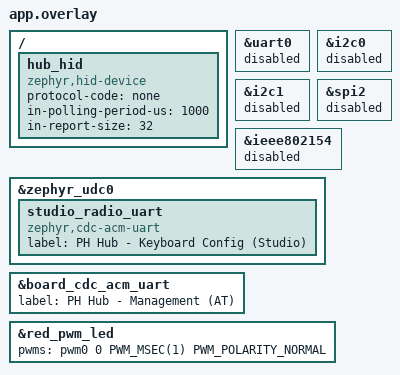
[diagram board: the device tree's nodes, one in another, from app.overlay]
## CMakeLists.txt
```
cmake_minimum_required(VERSION 3.20.0)
find_package(Zephyr REQUIRED HINTS $ENV{ZEPHYR_BASE})
project(eio_wireless_hub)
target_include_directories(app PRIVATE include src tinycrypt/include)
target_compile_options(app PRIVATE -include ${CMAKE_CURRENT_SOURCE_DIR}/include/hub-compat.h)
target_sources(app PRIVATE src/main.c src/usb.c src/usb-port-names.c src/radio.c src/ble-mouse.c src/diagnostics.c
    src/mouse-map.c src/peer-crypto.c src/peer-store.c src/input-merge.c
    src/studio-radio.c src/ph_lite_dongle_at.c src/dongle-led.c
    tinycrypt/source/aes_encrypt.c tinycrypt/source/ccm_mode.c tinycrypt/source/utils.c)
```

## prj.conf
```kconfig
CONFIG_BT=y
CONFIG_BT_CENTRAL=y
CONFIG_BT_SMP=y
# Many BLE HID mice implement legacy Just Works pairing, not LE SC.
CONFIG_BT_SMP_SC_PAIR_ONLY=n
CONFIG_BT_MAX_CONN=1
CONFIG_BT_MAX_PAIRED=1
CONFIG_BT_GATT_CLIENT=y
CONFIG_BT_GATT_DM=y
CONFIG_BT_HOGP=y
CONFIG_BT_SETTINGS=y
CONFIG_BT_PRIVACY=y
CONFIG_BT_ATT_TX_COUNT=5
CONFIG_BT_DEVICE_NAME="EIO Wireless Hub"
CONFIG_ESB=y
CONFIG_ESB_CLOCK_INIT=y
CONFIG_ESB_MPSL_TIMESLOT=y
CONFIG_MPSL_TIMESLOT_SESSION_COUNT=2
CONFIG_FLASH=y
CONFIG_FLASH_MAP=y
CONFIG_FLASH_PAGE_LAYOUT=y
CONFIG_NVS=y
CONFIG_SETTINGS=y
CONFIG_SETTINGS_NVS=y
CONFIG_USB_DEVICE_STACK_NEXT=y
CONFIG_USBD_HID_SUPPORT=y
CONFIG_CDC_ACM_SERIAL_INITIALIZE_AT_BOOT=n
CONFIG_SERIAL=y
CONFIG_UART_INTERRUPT_DRIVEN=y
CONFIG_UART_LINE_CTRL=y
CONFIG_CONSOLE=n
CONFIG_UART_CONSOLE=n
CONFIG_LOG=y
CONFIG_LOG_BACKEND_UART=n
CONFIG_USE_SEGGER_RTT=y
CONFIG_LOG_BACKEND_RTT=y
CONFIG_HWINFO=y
CONFIG_PWM=y
CONFIG_BUILD_OUTPUT_UF2=y
CONFIG_HEAP_MEM_POOL_SIZE=16384
CONFIG_BT_GATT_DM_MAX_ATTRS=96
CONFIG_BT_HOGP_REPORTS_MAX=24
CONFIG_MAIN_STACK_SIZE=4096
CONFIG_SYSTEM_WORKQUEUE_STACK_SIZE=4096
# CDC callbacks must not share a queue with BLE lifecycle/flash work.
CONFIG_USBD_CDC_ACM_WORKQUEUE=y
CONFIG_USBD_CDC_ACM_STACK_SIZE=4096
CONFIG_USBD_THREAD_STACK_SIZE=4096
CONFIG_UDC_NRF_THREAD_STACK_SIZE=1024
CONFIG_BT_TX_PROCESSOR_STACK_SIZE=1536
CONFIG_ASSERT=y
CONFIG_THREAD_STACK_INFO=y
CONFIG_REBOOT=y
CONFIG_ESB_MAX_PAYLOAD_LENGTH=32
CONFIG_ESB_PIPE_COUNT=2
CONFIG_ESB_TX_FIFO_SIZE=4
```

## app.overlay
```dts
&uart0 { status = "disabled"; };
&i2c0 { status = "disabled"; };
&i2c1 { status = "disabled"; };
&spi2 { status = "disabled"; };
&ieee802154 { status = "disabled"; };
&zephyr_udc0 {
    studio_radio_uart: studio_radio_uart {
        compatible = "zephyr,cdc-acm-uart";
        label = "PH Hub - Keyboard Config (Studio)";
    };
};
cdc_acm_uart0: &board_cdc_acm_uart { label = "PH Hub - Management (AT)"; };
dongle_status_led: &red_pwm_led { pwms = <&pwm0 0 PWM_MSEC(1) PWM_POLARITY_NORMAL>; };
/ {
    hub_hid: hub_hid {
        compatible = "zephyr,hid-device";
        protocol-code = "none";
        in-polling-period-us = <1000>;
        in-report-size = <32>;
    };
};
```

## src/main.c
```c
#include <zephyr/kernel.h>
#include <zephyr/bluetooth/bluetooth.h>
#include <zephyr/settings/settings.h>
#include <esb.h>
#include <zmk/2g4.h>
#include "hub.h"
#include "ble-mouse.h"
#include "hub-peer.h"
#include "diagnostics.h"
int main(void) {
    int err = bt_enable(NULL);
    if (err) return err;
    err = settings_load();
    if (err) return err;
    hub_peer_load_finish();
    err=hub_usb_init();if(err)return err;
    err=ble_mouse_init();if(err)return err;
    /* Keep USB diagnostics available after a fault without repeatedly writing
     * crypto epochs to flash in a reboot loop. AT+RST explicitly retries. */
    if(!hub_diagnostics_safe_mode())hub_radio_error=zmk_2g4_dongle_start();
    hub_radio_run();
    return 0;
}
```

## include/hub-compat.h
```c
#pragma once
#define CONFIG_ZMK_2G4_DONGLE 1
#define CONFIG_ZMK_2G4_AES_KEY "6D6164656279706864656973676EC0DE"
#define CONFIG_ZMK_2G4_ADDR_BASE_0 0x50
#define CONFIG_ZMK_2G4_ADDR_BASE_1 0x48
#define CONFIG_ZMK_2G4_ADDR_BASE_2 0x44
#define CONFIG_ZMK_2G4_ADDR_BASE_3 0x53
#define CONFIG_ZMK_2G4_ADDR_PREFIX 0x4e
#define CONFIG_ZMK_2G4_RF_CHANNEL 76
#define CONFIG_PH_LITE_DONGLE_AT_BOOTLOADER 1
```

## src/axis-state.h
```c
/* SPDX-License-Identifier: MIT */
#pragma once
#include <stdint.h>
static inline int16_t hub_axis_fresh(uint32_t now,uint32_t time,int16_t value){return now-time<=250?value:0;}
```

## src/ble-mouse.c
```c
/* SPDX-License-Identifier: MIT */
#include <zephyr/kernel.h>
#include <zephyr/bluetooth/bluetooth.h>
#include <zephyr/bluetooth/conn.h>
#include <zephyr/bluetooth/gatt.h>
#include <zephyr/bluetooth/hci.h>
#include <bluetooth/gatt_dm.h>
#include <bluetooth/services/hogp.h>
#include <zephyr/settings/settings.h>
#include <zephyr/sys/atomic.h>
#include <string.h>
#include "ble-mouse.h"
#include "hub.h"
#include "diagnostics.h"
static struct bt_hogp hogp;
static struct bt_conn *connection;
static struct mouse_map map;
static uint8_t report_map[2048];
static size_t map_size;
static atomic_t mouse_ready,packets,parse_errors,last_error;
static atomic_t disconnect_reason,security_level,connect_error;
static bool scanning,have_bond,discovering,protocol_configured;
static atomic_t resume_error_code,subscriptions_removed;
static int64_t pair_until;
static struct k_mutex map_lock;
struct candidate { bt_addr_le_t addr; int8_t rssi; char name[24]; };
static struct candidate candidates[8];
static unsigned candidate_count;
static struct k_mutex candidate_lock;
static struct k_work_delayable scan_work;
static struct k_work map_work;
static struct k_work subscribe_work;
static struct k_work_delayable resume_work;
static struct k_work connect_work;
static bt_addr_le_t reconnect_addr;
static bool radio_paused;
static int resume_error;
static void resume_handler(struct k_work *work) {
    if(!radio_paused)return;
    int err=hub_radio_pause(false);
    resume_error=err;
    if(err){k_work_reschedule(&resume_work,K_MSEC(50));return;}
    radio_paused=false;
}
static void scan_handler(struct k_work *work);
static void subscribe_handler(struct k_work *work);
static void map_handler(struct k_work *work);
static bool name_ad(struct bt_data *d,void *ctx) {
    struct { bool hid; char name[24]; } *a=ctx;
    if(d->type==BT_DATA_UUID16_ALL || d->type==BT_DATA_UUID16_SOME) {
        for(size_t i=0;i+1<d->data_len;i+=2)if(d->data[i]==0x12 && d->data[i+1]==0x18)a->hid=true;
    } else if(d->type==BT_DATA_GAP_APPEARANCE && d->data_len==2) {
        if(d->data[0]==0xc2 && d->data[1]==3)a->hid=true;
    } else if(d->type==BT_DATA_NAME_COMPLETE || d->type==BT_DATA_NAME_SHORTENED) {
        size_t n=MIN(d->data_len,sizeof(a->name)-1);
        for(size_t i=0;i<n;i++)a->name[i]=d->data[i]>=32 && d->data[i]<127?d->data[i]:'?';
    }
    return true;
}
static int connect_addr(const bt_addr_le_t *addr) {
    hub_diagnostic_stage(30);
    if(connection)return -EISCONN;
    bt_le_scan_stop();scanning=false;
    // Temporarily release ESB slots while the first BLE connection events settle.
    // Resume even if connection setup fails, so the keyboard cannot stay paused.
    if(!hub_radio_pause(true)){radio_paused=true;k_msleep(30);}
    k_work_reschedule(&resume_work,K_SECONDS(5));
    struct bt_conn_le_create_param create=BT_CONN_LE_CREATE_PARAM_INIT(BT_CONN_LE_OPT_NONE,160,16);
    struct bt_le_conn_param params={.interval_min=12,.interval_max=24,.latency=0,.timeout=400};
    int err=bt_conn_le_create(addr,&create,&params,&connection);
    atomic_set(&last_error,err);
    if(err)k_work_reschedule(&scan_work,K_SECONDS(1));
    return err;
}
static void connect_handler(struct k_work *work){connect_addr(&reconnect_addr);}
static void scan_recv(const struct bt_le_scan_recv_info *info,struct net_buf_simple *ad) {
    if(connection || !(info->adv_props&BT_GAP_ADV_PROP_CONNECTABLE))return;
    if(have_bond && bt_le_bond_exists(BT_ID_DEFAULT,info->addr)) {
        reconnect_addr=*info->addr;k_work_submit(&connect_work);return;
    }
    if(k_uptime_get()>=pair_until)return;
    struct { bool hid; char name[24]; } fields={0};
    struct net_buf_simple_state saved;net_buf_simple_save(ad,&saved);
    bt_data_parse(ad,name_ad,&fields);net_buf_simple_restore(ad,&saved);
    if(!fields.hid)return;
    k_mutex_lock(&candidate_lock,K_FOREVER);
    unsigned index;
    for(index=0;index<candidate_count;index++)if(!bt_addr_le_cmp(info->addr,&candidates[index].addr))break;
    if(index<ARRAY_SIZE(candidates)) {
        if(index==candidate_count)candidate_count++;
        candidates[index].addr=*info->addr;candidates[index].rssi=info->rssi;
        if(fields.name[0])memcpy(candidates[index].name,fields.name,sizeof(fields.name));
    }
    k_mutex_unlock(&candidate_lock);
}
static struct bt_le_scan_cb scan_callbacks={.recv=scan_recv};
static void scan_handler(struct k_work *work) {
    if(connection)return;
    bool pairing=k_uptime_get()<pair_until;
    if(!pairing && !have_bond) {
        if(scanning)bt_le_scan_stop();
        scanning=false;return;
    }
    if(!scanning) {
        // 10% scan duty leaves most radio time available to the keyboard.
        struct bt_le_scan_param params={.type=pairing?BT_LE_SCAN_TYPE_ACTIVE:BT_LE_SCAN_TYPE_PASSIVE,
            .options=BT_LE_SCAN_OPT_NONE,.interval=160,.window=16};
        int err=bt_le_scan_start(&params,NULL);
        scanning=!err;if(err)atomic_set(&last_error,err);
    }
    k_work_reschedule(&scan_work,K_SECONDS(1));
}
static uint8_t report_received(struct bt_hogp *h,struct bt_hogp_rep_info *rep,uint8_t err,const uint8_t *data) {
    if(err || !data) {
        atomic_clear(&mouse_ready);
        atomic_set(&last_error,err?err:-ENODATA);
        atomic_inc(&subscriptions_removed);hub_mouse_release(2);
        return BT_GATT_ITER_STOP;
    }
    if(!atomic_get(&mouse_ready))return BT_GATT_ITER_CONTINUE;
    struct mouse_event e;int rc;
    k_mutex_lock(&map_lock,K_FOREVER);
    rc=mouse_map_decode(&map,bt_hogp_rep_id(rep),data,bt_hogp_rep_size(rep),&e);
    k_mutex_unlock(&map_lock);
    if(!rc){hub_mouse_event(2,&e);atomic_inc(&packets);}
    else atomic_inc(&parse_errors);
    return BT_GATT_ITER_CONTINUE;
}
static void subscribe_handler(struct k_work *work) {
    if(!connection)return;
    k_mutex_lock(&map_lock,K_FOREVER);
    int err=mouse_map_parse(&map,report_map,map_size);
    k_mutex_unlock(&map_lock);
    if(err){atomic_set(&last_error,err);return;}
    // Report protocol preserves wheel, extra buttons and non-8-bit axes.
    if(!protocol_configured || bt_hogp_pm_get(&hogp)!=BT_HIDS_PM_REPORT) {
        /* Send Report mode explicitly even if the characteristic already reads
         * Report. Some peripherals do not activate input after first pairing
         * until the host writes its desired mode. Set before synchronous cb. */
        protocol_configured=true;
        err=bt_hogp_pm_write(&hogp,BT_HIDS_PM_REPORT);
        if(!err)return; // pm_update schedules the subscription work.
        if(err!=-EOPNOTSUPP){atomic_set(&last_error,err);return;}
    }
    bool subscribed=false;
    struct bt_hogp_rep_info *r=NULL;
    while((r=bt_hogp_rep_next(&hogp,r))) {
        bool mouse=false;
        for(int i=0;i<map.field_count;i++)if(map.fields[i].id==bt_hogp_rep_id(r))mouse=true;
        if(mouse && bt_hogp_rep_type(r)==BT_HIDS_REPORT_TYPE_INPUT) {
            err=bt_hogp_rep_subscribe(&hogp,r,report_received);
            if(err && err!=-EALREADY){atomic_set(&last_error,err);return;}
            subscribed=true;
        }
    }
    atomic_set(&mouse_ready,subscribed);atomic_set(&last_error,subscribed?0:-ENOTSUP);
    if(subscribed)atomic_set(&resume_error_code,bt_hogp_exit_suspend(&hogp));
    k_work_reschedule(&resume_work,K_MSEC(100));
}
static void map_chunk(struct bt_hogp *h,uint8_t err,const uint8_t *data,size_t size,size_t offset) {
    if(!connection)return;
    if(err==BT_ATT_ERR_INVALID_OFFSET && offset==map_size && offset>0) {
        k_work_submit(&subscribe_work);return;
    }
    if(err){atomic_set(&last_error,err);return;}
    if(offset!=map_size || offset+size>sizeof(report_map)){atomic_set(&last_error,-E2BIG);return;}
    if(!data || !size){k_work_submit(&subscribe_work);return;}
    memcpy(report_map+offset,data,size);map_size+=size;
    k_work_submit(&map_work);
}
static void map_handler(struct k_work *work) {
    if(!connection)return;
    int err=bt_hogp_map_read(&hogp,map_chunk,map_size,K_NO_WAIT);
    atomic_set(&last_error,err);
}
static void ready_cb(struct bt_hogp *h){map_size=0;k_work_submit(&map_work);}
static void prep_error(struct bt_hogp *h,int err){atomic_set(&last_error,err);}
static void pm_update(struct bt_hogp *h){if(map_size)k_work_submit(&subscribe_work);}
static void discovery_done(struct bt_gatt_dm *dm,void *context) {
    int err=bt_hogp_handles_assign(dm,&hogp);bt_gatt_dm_data_release(dm);
    atomic_set(&last_error,err);
}
static void discovery_missing(struct bt_conn *conn,void *ctx){atomic_set(&last_error,-ENOTSUP);}
static void discovery_error(struct bt_conn *conn,int err,void *ctx){atomic_set(&last_error,err);}
static const struct bt_gatt_dm_cb discovery_cb={.completed=discovery_done,
    .service_not_found=discovery_missing,.error_found=discovery_error};
static void discover(struct bt_conn *conn) {
    if(discovering)return;
    discovering=true;
    int err=bt_gatt_dm_start(conn,BT_UUID_HIDS,&discovery_cb,NULL);
    atomic_set(&last_error,err);
}
static void connected_cb(struct bt_conn *conn,uint8_t err) {
    protocol_configured=false;
    hub_diagnostic_stage(40);
    atomic_set(&connect_error,err);
    if(err) {
        atomic_set(&last_error,err);
        if(connection){bt_conn_unref(connection);connection=NULL;}
        k_work_reschedule(&scan_work,K_SECONDS(1));return;
    }
    int rc=bt_conn_set_security(conn,BT_SECURITY_L2);
    if(rc)atomic_set(&last_error,rc);
    else if(bt_conn_get_security(conn)>=BT_SECURITY_L2)discover(conn);
}
static void security_changed(struct bt_conn *conn,bt_security_t level,enum bt_security_err err) {
    hub_diagnostic_stage(41);
    atomic_set(&security_level,level);
    if(err){atomic_set(&last_error,err);return;}
    if(level>=BT_SECURITY_L2){have_bond=true;discover(conn);}
}
static void disconnected_cb(struct bt_conn *conn,uint8_t reason) {
    protocol_configured=false;
    atomic_set(&disconnect_reason,reason);atomic_clear(&security_level);
    atomic_clear(&mouse_ready);hub_mouse_release(2);
    k_work_cancel(&map_work);k_work_cancel(&subscribe_work);
    bt_hogp_release(&hogp);discovering=false;map_size=0;
    if(connection){bt_conn_unref(connection);connection=NULL;}
    k_work_reschedule(&scan_work,K_SECONDS(1));
    k_work_reschedule(&resume_work,K_MSEC(50));
}
BT_CONN_CB_DEFINE(conn_callbacks)={.connected=connected_cb,.disconnected=disconnected_cb,.security_changed=security_changed};
static void bond_found(const struct bt_bond_info *info,void *ctx){have_bond=true;}
int ble_mouse_init(void) {
    k_mutex_init(&map_lock);k_mutex_init(&candidate_lock);
    k_work_init_delayable(&scan_work,scan_handler);k_work_init(&map_work,map_handler);
    k_work_init(&subscribe_work,subscribe_handler);
    k_work_init_delayable(&resume_work,resume_handler);
    k_work_init(&connect_work,connect_handler);
    const struct bt_hogp_init_params params={.ready_cb=ready_cb,.prep_error_cb=prep_error,.pm_update_cb=pm_update};
    bt_hogp_init(&hogp,&params);
    bt_le_scan_cb_register(&scan_callbacks);
    bt_foreach_bond(BT_ID_DEFAULT,bond_found,NULL);
    k_work_reschedule(&scan_work,K_MSEC(500));return 0;
}
int ble_mouse_pair(void) {
    if(connection || have_bond)return -EALREADY;
    k_mutex_lock(&candidate_lock,K_FOREVER);candidate_count=0;memset(candidates,0,sizeof(candidates));k_mutex_unlock(&candidate_lock);
    pair_until=k_uptime_get()+30000;
    k_work_reschedule(&scan_work,K_NO_WAIT);return 0;
}
int ble_mouse_connect(unsigned index) {
    if(connection || k_uptime_get()>=pair_until)return -EACCES;
    k_mutex_lock(&candidate_lock,K_FOREVER);
    if(index>=candidate_count){k_mutex_unlock(&candidate_lock);return -EINVAL;}
    bt_addr_le_t addr=candidates[index].addr;k_mutex_unlock(&candidate_lock);
    return connect_addr(&addr);
}
int ble_mouse_clear(void) {
    hub_diagnostic_stage(50);
    /* Discard stale scan results and queued auto-connect attempts. A new
     * pairing window must discover fresh advertisements after forgetting. */
    k_work_cancel(&connect_work);
    k_work_cancel_delayable(&scan_work);
    have_bond=false;pair_until=0;
    if(connection)bt_conn_disconnect(connection,BT_HCI_ERR_REMOTE_USER_TERM_CONN);
    if(scanning)bt_le_scan_stop();
    scanning=false;
    k_mutex_lock(&candidate_lock,K_FOREVER);
    candidate_count=0;memset(candidates,0,sizeof(candidates));
    k_mutex_unlock(&candidate_lock);
    return bt_unpair(BT_ID_DEFAULT,BT_ADDR_LE_ANY);
}
int ble_mouse_resume(void) {
    if(!connection || !bt_hogp_ready_check(&hogp))return -EAGAIN;
    int err=bt_hogp_exit_suspend(&hogp);
    atomic_set(&resume_error_code,err);return err;
}
void ble_mouse_status(char *out,size_t size) {
    size_t used=snprintk(out,size,"BLE_STATE=%s\r\nBLE_RX=%ld\r\nBLE_PARSE_FAIL=%ld\r\nBLE_ERROR=%ld\r\nBLE_REASON=%ld\r\nBLE_SEC=%ld\r\nBLE_CONN_ERR=%ld\r\nBLE_MAP=%u\r\nRADIO_PAUSED=%d\r\nRADIO_RESUME_ERROR=%d\r\n",
        atomic_get(&mouse_ready)?"READY":connection?"CONNECTING":scanning?"SCANNING":"IDLE",
        (long)atomic_get(&packets),(long)atomic_get(&parse_errors),(long)atomic_get(&last_error),
        (long)atomic_get(&disconnect_reason),(long)atomic_get(&security_level),
        (long)atomic_get(&connect_error),(unsigned)map_size,radio_paused,resume_error);
    if(used+1<size)used+=snprintk(out+used,size-used,"BLE_RESUME_ERROR=%ld\r\nBLE_SUBSCRIPTIONS_REMOVED=%ld\r\n",
        (long)atomic_get(&resume_error_code),(long)atomic_get(&subscriptions_removed));
    k_mutex_lock(&candidate_lock,K_FOREVER);
    for(unsigned i=0;i<candidate_count && used+1<size;i++) {
        int n=snprintk(out+used,size-used,"BLE_DEVICE=%u,%d,%s\r\n",i,candidates[i].rssi,
            candidates[i].name[0]?candidates[i].name:"BLE HID");
        used+=MIN(n,size-used-1);
    }
    k_mutex_unlock(&candidate_lock);
}
```

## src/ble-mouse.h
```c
#pragma once
#include <stddef.h>
int ble_mouse_init(void);
int ble_mouse_pair(void);
int ble_mouse_connect(unsigned index);
int ble_mouse_clear(void);
int ble_mouse_resume(void);
void ble_mouse_status(char *out,size_t size);
```

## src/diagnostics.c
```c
#include <zephyr/kernel.h>
#include <zephyr/fatal.h>
#include <zephyr/init.h>
#include <zephyr/arch/arm/exception.h>
#include <hal/nrf_power.h>
#include "diagnostics.h"

/* RAM only: survive a software fault reset without touching pairing/NVS. */
static __noinit volatile struct {
    uint32_t magic, reason, pc, stage, line;
    char file[96];
} retained;
static uint32_t last_reason, last_pc, last_stage, last_line;
static char last_file[96];
static volatile uint32_t stage;
static int diagnostics_init(void) {
    if (retained.magic == 0x48554245) {
        last_reason=retained.reason;last_pc=retained.pc;last_stage=retained.stage;
        last_line=retained.line;
        for(unsigned i=0;i<sizeof(last_file);i++)last_file[i]=retained.file[i];
        last_file[sizeof(last_file)-1]=0;
    }
    retained.magic=0;return 0;
}
SYS_INIT(diagnostics_init,PRE_KERNEL_1,0);
void hub_diagnostic_stage(unsigned int value){stage=value;}
bool hub_diagnostics_safe_mode(void){return last_reason!=0;}
void hub_diagnostics_status(char *out,size_t size) {
    snprintk(out,size,"HUB_FAULT=%u\r\nHUB_FAULT_PC=%08X\r\nHUB_FAULT_STAGE=%u\r\nHUB_TRACE_STAGE=%u\r\nHUB_ASSERT_FILE=%s\r\nHUB_ASSERT_LINE=%u\r\nHUB_SAFE_MODE=%u\r\n",
             last_reason,last_pc,last_stage,stage,last_file,last_line,hub_diagnostics_safe_mode());
}
void k_sys_fatal_error_handler(unsigned int reason,const struct arch_esf *esf) {
    retained.reason=reason+1; /* zero means no retained fault */
    retained.pc=esf?esf->basic.pc:0;retained.stage=stage;
    retained.line=0;retained.file[0]=0;
    retained.magic=0x48554245;
    __DSB();NVIC_SystemReset();
    for(;;){}
}
void assert_post_action(const char *file,unsigned int line) {
    retained.reason=5;retained.pc=(uint32_t)__builtin_return_address(0);
    retained.stage=stage;retained.line=line;
    unsigned i=0;
    while(file && file[i] && i<sizeof(retained.file)-1){retained.file[i]=file[i];i++;}
    retained.file[i]=0;retained.magic=0x48554245;
    __DSB();NVIC_SystemReset();
    for(;;){}
}
```

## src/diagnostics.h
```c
#pragma once
#include <stddef.h>
#include <stdbool.h>
bool hub_diagnostics_safe_mode(void);
void hub_diagnostic_stage(unsigned int stage);
void hub_diagnostics_status(char *out, size_t size);
```

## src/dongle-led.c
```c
#include <zephyr/device.h>
#include <zephyr/drivers/pwm.h>
#include <zephyr/init.h>
#include <zephyr/kernel.h>
#include <zephyr/settings/settings.h>
#include <zephyr/sys/byteorder.h>
#include <zmk/2g4.h>
#include "led-control.h"
#include "led-config.h"
#include "led-pattern.h"
#include "led-link.h"
#include "led-motion.h"
#include "hub-peer.h"

static const struct pwm_dt_spec led = PWM_DT_SPEC_GET(DT_NODELABEL(dongle_status_led));
static struct led_config config = {0,100,20,2000}, saved = {0,100,20,2000};
static struct k_spinlock lock;
static struct k_work_delayable led_work;
static int64_t identify_until;
static bool low;
static int previous_threshold = 20;
static struct led_link_state link_state;
static int settings_set(const char *name, size_t len, settings_read_cb read, void *arg) {
    if (strcmp(name,"config")) return -ENOENT;
    uint8_t data[6];
    if (len != sizeof(data)) return -EINVAL;
    int rc = read(arg,data,sizeof(data));
    if (rc < 0) return rc;
    if (rc != sizeof(data) || data[0] != 1) return -EINVAL;
    struct led_config c = {data[1],data[2],data[3],sys_get_le16(&data[4])};
    if (!led_config_valid(&c)) return -EINVAL;
    k_spinlock_key_t key = k_spin_lock(&lock); config = saved = c; k_spin_unlock(&lock,key);
    return 0;
}
SETTINGS_STATIC_HANDLER_DEFINE(dongle_led,"dongle_led",NULL,settings_set,NULL,NULL);
int dongle_led_configure(const char *args) {
    struct led_config c;
    if (led_config_parse(args,&c)) return -EINVAL;
    k_spinlock_key_t key = k_spin_lock(&lock); config = c; k_spin_unlock(&lock,key);
    return 0;
}
int dongle_led_save(void) {
    k_spinlock_key_t key = k_spin_lock(&lock); struct led_config c = config; k_spin_unlock(&lock,key);
    uint8_t data[6] = {1,c.mode,c.brightness,c.threshold,0,0}; sys_put_le16(c.period,&data[4]);
    int rc = settings_save_one("dongle_led/config",data,sizeof(data));
    if (!rc) { key = k_spin_lock(&lock); saved = c; k_spin_unlock(&lock,key); }
    return rc;
}
void dongle_led_identify(void) {
    k_spinlock_key_t key = k_spin_lock(&lock); identify_until = k_uptime_get()+5000; k_spin_unlock(&lock,key);
}
void dongle_led_status(char *out,size_t size) {
    k_spinlock_key_t key = k_spin_lock(&lock); struct led_config c = config, s = saved; k_spin_unlock(&lock,key);
    bool dirty = c.mode != s.mode || c.brightness != s.brightness || c.threshold != s.threshold || c.period != s.period;
    snprintk(out,size,"LED_CAPS=1\r\nLED_MODE=%s\r\nLED_BRIGHTNESS=%u\r\nLED_LOW_PCT=%u\r\nLED_PERIOD_MS=%u\r\nLED_DIRTY=%d\r\n",
             c.mode==0?"AUTO":c.mode==1?"ON":"OFF",c.brightness,c.threshold,c.period,dirty);
}
static void update_led(struct k_work *work) {
    k_spinlock_key_t key = k_spin_lock(&lock); struct led_config c = config; int64_t until = identify_until; k_spin_unlock(&lock,key);
    int64_t now = k_uptime_get();
    bool connected = hub_any_keyboard_connected(); int percent = hub_lowest_battery();
    if (previous_threshold != c.threshold) low = false;
    previous_threshold = c.threshold;
    low = connected && percent >= 0 && (low ? percent < c.threshold+5 : percent <= c.threshold);
    bool on = c.mode==1 || (c.mode==0 && dongle_led_on((uint32_t)((now%c.period)*2000/c.period),connected,percent,low));
    // Identification remains visible even when the user configured off/zero brightness.
    bool identify = now < until;
    uint8_t mask = (hub_keyboard_connected(0) ? 1 : 0) |
                   (hub_keyboard_connected(1) ? 2 : 0);
    uint8_t locked = (hub_keyboard_motion(0)==MOTION_LOCKED ? 1 : 0) |
                     (hub_keyboard_motion(1)==MOTION_LOCKED ? 2 : 0);
    enum led_motion_mode motion_mode = led_motion_select(mask,locked);
    bool link_on;
    bool link_event = led_link_update(&link_state, (uint32_t)now, mask,
                        c.mode != 2 && c.brightness > 0, identify, &link_on);
    if (link_event) {
        on = link_on;
    }
    if (identify) on = now%250 < 125;
    uint32_t duty = identify ? 100 : c.brightness;
    /* Identify, connection edges and low-battery warning keep priority. */
    if (c.mode==0 && !identify && !link_event && !low && motion_mode!=LED_MOTION_NORMAL) {
        on = true;
        duty = c.brightness * led_motion_level(motion_mode,(uint32_t)now)/100;
    }
    pwm_set_dt(&led,led.period,on ? led.period*duty/100 : 0);
    k_work_reschedule(&led_work,K_MSEC(25));
}
static int dongle_led_init(void) {
    if (!pwm_is_ready_dt(&led)) return -ENODEV;
    int err = pwm_set_dt(&led,led.period,0); if (err) return err;
    k_work_init_delayable(&led_work,update_led); k_work_schedule(&led_work,K_NO_WAIT); return 0;
}
SYS_INIT(dongle_led_init,APPLICATION,96);
```

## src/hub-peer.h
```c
#pragma once
#include <zmk/2g4_crypto.h>
#include "motion-telemetry.h"
#define HUB_PEERS 2
unsigned hub_peer_target(void);
int hub_peer_select(unsigned slot);
int hub_peer_select_session(unsigned slot);
bool hub_peer_enabled(unsigned slot);
bool hub_peer_paired(unsigned slot);
void hub_peer_addr(unsigned slot,struct zmk_2g4_addr *out);
uint32_t hub_peer_key_id(unsigned slot);
int hub_peer_pair(unsigned slot,const uint8_t key[16],const struct zmk_2g4_addr *addr);
int hub_peer_clear(unsigned slot);
int hub_peer_encrypt(unsigned slot,uint8_t *data,size_t len,size_t cap);
int hub_peer_decrypt(unsigned slot,uint8_t *data,size_t len);
void hub_peer_load_finish(void);
int hub_radio_reconfigure(void);
void hub_radio_release(unsigned slot);
void hub_peer_status(char *out,size_t size);
bool hub_any_keyboard_connected(void);
int hub_lowest_battery(void);
bool hub_keyboard_connected(unsigned slot);
enum motion_status hub_keyboard_motion(unsigned slot);
int hub_keyboard_battery(unsigned slot);
void hub_keyboard_stats(unsigned slot,uint32_t *rx,uint32_t *fail,uint32_t *drop);
bool studio_radio_busy(void);
```

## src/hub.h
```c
#pragma once
#include <stdint.h>
#include <stddef.h>
#include "mouse-map.h"
int hub_usb_init(void);
int hub_usb_report(uint8_t id,const uint8_t *data,size_t len);
void hub_mouse_event(unsigned source,const struct mouse_event *event);
void hub_mouse_release(unsigned source);
void hub_radio_run(void);
int hub_radio_pause(bool pause);
extern int hub_radio_error;

void hub_axis_event(unsigned slot,int16_t axis);
```

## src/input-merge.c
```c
/* SPDX-License-Identifier: MIT */
#include "input-merge.h"
#include <string.h>
void merge_keyboard(const struct input_merge *s,uint8_t out[15]) {
    for(int i=0;i<15;i++)out[i]=s->keyboard[0][i]|s->keyboard[1][i];
    out[1]=0;
}
void merge_consumer(const struct input_merge *s,uint8_t out[24]) {
    memset(out,0,24);unsigned used=0;
    for(int slot=0;slot<2;slot++)for(int i=0;i<12;i+=2) {
        const uint8_t *p=s->consumer[slot]+i;if(!p[0] && !p[1])continue;
        unsigned j;for(j=0;j<used;j++)if(out[2*j]==p[0] && out[2*j+1]==p[1])break;
        if(j==used){out[2*used]=p[0];out[2*used+1]=p[1];used++;}
    }
}
```

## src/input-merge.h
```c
/* SPDX-License-Identifier: MIT */
#pragma once
#include <stdint.h>
struct input_merge { uint8_t keyboard[2][15],consumer[2][12]; };
void merge_keyboard(const struct input_merge *s,uint8_t out[15]);
void merge_consumer(const struct input_merge *s,uint8_t out[24]);
```

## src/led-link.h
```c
/* SPDX-License-Identifier: MIT */
#pragma once
#include <stdbool.h>
#include <stdint.h>

#define LED_LINK_QUEUE 8
struct led_link_state {
    uint8_t mask, head, count;
    bool events[LED_LINK_QUEUE], active, connected;
    uint32_t started;
};
static inline void led_link_push(struct led_link_state *s, bool connected) {
    /* If transitions flap excessively, keep the newest bounded history. */
    if (s->count == LED_LINK_QUEUE) {
        s->head = (s->head + 1) % LED_LINK_QUEUE;
        s->count--;
    }
    s->events[(s->head + s->count++) % LED_LINK_QUEUE] = connected;
}
/* Poll connection state, then optionally override the baseline LED level.
 * enabled respects OFF/brightness=0; identify keeps its existing priority.
 * All timing is nonblocking and independent of the configured idle period. */
static inline bool led_link_update(struct led_link_state *s, uint32_t now,
                                   uint8_t mask, bool enabled, bool identify, bool *on) {
    uint8_t changed = (s->mask ^ mask) & 3;
    s->mask = mask;
    if (!enabled || identify) {
        s->active = false;
        s->count = s->head = 0;
        return false;
    }
    for (unsigned slot = 0; slot < 2; slot++) {
        if (changed & (1u << slot)) { led_link_push(s, mask & (1u << slot)); }
    }
    if (s->active) {
        uint32_t duration = s->connected ? 600 : 1100;
        if (now - s->started >= duration) { s->active = false; }
    }
    if (!s->active && s->count) {
        s->connected = s->events[s->head];
        s->head = (s->head + 1) % LED_LINK_QUEUE;
        s->count--;
        s->active = true;
        s->started = now;
    }
    if (!s->active) { return false; }
    uint32_t ms = now - s->started;
    /* Begin dark so both pulses are visible even over steady ON. */
    *on = s->connected ? ((ms >= 100 && ms < 200) || (ms >= 300 && ms < 400))
                       : ((ms >= 100 && ms < 400) || (ms >= 600 && ms < 900));
    return true;
}
```
